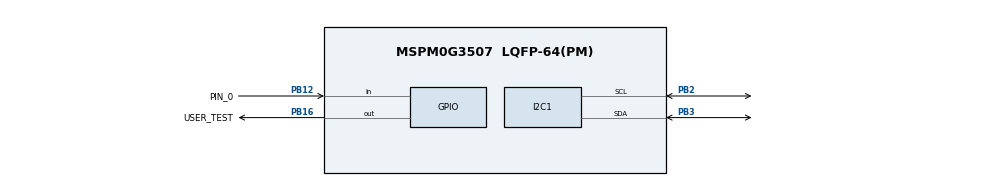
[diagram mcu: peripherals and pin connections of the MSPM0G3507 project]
/**
 * These arguments were used when this file was generated. They will be automatically applied on subsequent loads
 * via the GUI or CLI. Run CLI with '--help' for additional information on how to override these arguments.
 * @cliArgs --device "MSPM0G350X" --part "Default" --package "LQFP-64(PM)" --product "mspm0_sdk@2.07.00.06"
 * @v2CliArgs --device "MSPM0G3507" --package "LQFP-64(PM)" --product "mspm0_sdk@2.07.00.06"
 * @versions {"tool":"1.25.0+4268"}
 */

/**
 * Import the modules used in this configuration.
 */
const ADC12  = scripting.addModule("/ti/driverlib/ADC12", {}, false);
const ADC121 = ADC12.addInstance();
const GPIO   = scripting.addModule("/ti/driverlib/GPIO", {}, false);
const GPIO1  = GPIO.addInstance();
const I2C    = scripting.addModule("/ti/driverlib/I2C", {}, false);
const I2C1   = I2C.addInstance();
const SYSCTL = scripting.addModule("/ti/driverlib/SYSCTL");

/**
 * Write custom configuration values to the imported modules.
 */
ADC121.$name                      = "ADC12_0";
ADC121.enabledInterrupts          = ["DL_ADC12_INTERRUPT_DMA_DONE","DL_ADC12_INTERRUPT_MEM0_RESULT_LOADED","DL_ADC12_INTERRUPT_OVERFLOW","DL_ADC12_INTERRUPT_TRIG_OVF","DL_ADC12_INTERRUPT_UNDERFLOW"];
ADC121.adcPin0Config.$name        = "ti_driverlib_gpio_GPIOPinGeneric0";
ADC121.adcPin0Config.enableConfig = true;

const Board = scripting.addModule("/ti/driverlib/Board", {}, false);

GPIO1.$name                         = "GPIO_LEDS";
GPIO1.port                          = "PORTB";
GPIO1.associatedPins.create(5);
GPIO1.associatedPins[0].$name       = "USER_LED_1";
GPIO1.associatedPins[0].assignedPin = "22";
GPIO1.associatedPins[1].$name       = "USER_LED_2";
GPIO1.associatedPins[1].assignedPin = "26";
GPIO1.associatedPins[2].$name       = "USER_LED_3";
GPIO1.associatedPins[2].assignedPin = "27";
GPIO1.associatedPins[3].$name       = "USER_TEST";
GPIO1.associatedPins[3].pin.$assign = "PB16";
GPIO1.associatedPins[4].$name       = "PIN_0";
GPIO1.associatedPins[4].direction   = "INPUT";
GPIO1.associatedPins[4].pin.$assign = "PB12";

I2C1.$name                     = "I2C_0";
I2C1.peripheral.sdaPin.$assign = "PB3";
I2C1.peripheral.sclPin.$assign = "PB2";
I2C1.sdaPinConfig.$name        = "ti_driverlib_gpio_GPIOPinGeneric1";
I2C1.sclPinConfig.$name        = "ti_driverlib_gpio_GPIOPinGeneric2";

SYSCTL.forceDefaultClkConfig = true;
SYSCTL.clockTreeEn           = true;

/**
 * Pinmux solution for unlocked pins/peripherals. This ensures that minor changes to the automatic solver in a future
 * version of the tool will not impact the pinmux you originally saw.  These lines can be completely deleted in order to
 * re-solve from scratch.
 */
ADC121.peripheral.$suggestSolution           = "ADC1";
ADC121.peripheral.adcPin0.$suggestSolution   = "PA15";
Board.peripheral.$suggestSolution            = "DEBUGSS";
Board.peripheral.swclkPin.$suggestSolution   = "PA20";
Board.peripheral.swdioPin.$suggestSolution   = "PA19";
GPIO1.associatedPins[0].pin.$suggestSolution = "PB22";
GPIO1.associatedPins[1].pin.$suggestSolution = "PB26";
GPIO1.associatedPins[2].pin.$suggestSolution = "PB27";
I2C1.peripheral.$suggestSolution             = "I2C1";
